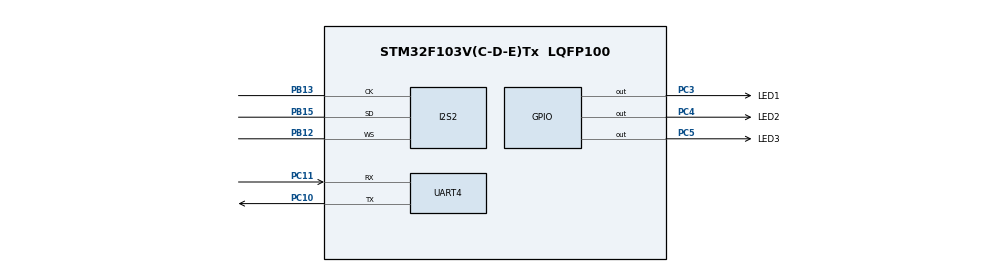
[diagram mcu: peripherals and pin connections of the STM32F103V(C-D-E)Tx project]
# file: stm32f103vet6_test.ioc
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I2S2.ErrorAudioFreq=0.8 %
I2S2.Instance=SPI$Index
I2S2.RealAudioFreq=8.064 KHz
I2S2.VirtualMode=I2S_MODE_SLAVE
Mcu.Family=STM32F1
Mcu.Name=STM32F103V(C-D-E)Tx
Mcu.Package=LQFP100
NVIC.PriorityGroup=NVIC_PRIORITYGROUP_4
PA13.Mode=JTAG_5_pins
PA13.Signal=SYS_JTMS-SWDIO
PA14.Mode=JTAG_5_pins
PA14.Signal=SYS_JTCK-SWCLK
PA15.Mode=JTAG_5_pins
PA15.Signal=SYS_JTDI
PB12.Mode=Half_Duplex_Slave_RX
PB12.Signal=I2S2_WS
PB13.Mode=Half_Duplex_Slave_RX
PB13.Signal=I2S2_CK
PB15.Mode=Half_Duplex_Slave_RX
PB15.Signal=I2S2_SD
PB3.Mode=JTAG_5_pins
PB3.Signal=SYS_JTDO-TRACESWO
PB4.Mode=JTAG_5_pins
PB4.Signal=SYS_NJTRST
PC10.Mode=Asynchronous
PC10.Signal=UART4_TX
PC11.Mode=Asynchronous
PC11.Signal=UART4_RX
PC3.GPIO_Label=LED1
PC3.PinState=GPIO_PIN_SET
PC3.Signal=GPIO_Output
PC4.GPIO_Label=LED2
PC4.PinState=GPIO_PIN_SET
PC4.Signal=GPIO_Output
PC5.GPIO_Label=LED3
PC5.PinState=GPIO_PIN_SET
PC5.Signal=GPIO_Output
ProjectManager.HeapSize=0x200
ProjectManager.StackSize=0x400
ProjectManager.TargetToolchain=SW4STM32
RCC.APB1Freq_Value=8000000
RCC.APB2Freq_Value=8000000
UART4.VirtualMode=Asynchronous
board=custom

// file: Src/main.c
/* USER CODE BEGIN Header */
/**
  ******************************************************************************
  * @file           : main.c
  * @brief          : Main program body
  ******************************************************************************
  * @attention
  *
  * <h2><center>&copy; Copyright (c) 2021 STMicroelectronics.
  * All rights reserved.</center></h2>
  *
  * This software component is licensed by ST under BSD 3-Clause license,
  * the "License"; You may not use this file except in compliance with the
  * License. You may obtain a copy of the License at:
  *                        opensource.org/licenses/BSD-3-Clause
  *
  ******************************************************************************
  */
/* USER CODE END Header */
#include "main.h"

I2S_HandleTypeDef hi2s2;

UART_HandleTypeDef huart4;

void SystemClock_Config(void);
static void MX_GPIO_Init(void);
static void MX_I2S2_Init(void);
static void MX_UART4_Init(void);

int main(void)
{

  /* MCU Configuration--------------------------------------------------------*/

  /* Reset of all peripherals, Initializes the Flash interface and the Systick. */
  HAL_Init();

  /* Configure the system clock */
  SystemClock_Config();

  /* Initialize all configured peripherals */
  MX_GPIO_Init();
  MX_I2S2_Init();
  MX_UART4_Init();

  /* Infinite loop */
  /* USER CODE BEGIN WHILE */
  while (1)
  {
      HAL_GPIO_WritePin(LED1_GPIO_Port,LED1_Pin,GPIO_PIN_SET);
      HAL_GPIO_WritePin(LED1_GPIO_Port,LED1_Pin,GPIO_PIN_RESET);
    /* USER CODE END WHILE */

  }
}

void SystemClock_Config(void)
{
  RCC_OscInitTypeDef RCC_OscInitStruct = {0};
  RCC_ClkInitTypeDef RCC_ClkInitStruct = {0};
  RCC_PeriphCLKInitTypeDef PeriphClkInit = {0};

  /** Initializes the RCC Oscillators according to the specified parameters
  * in the RCC_OscInitTypeDef structure.
  */
  RCC_OscInitStruct.OscillatorType = RCC_OSCILLATORTYPE_HSI;
  RCC_OscInitStruct.HSIState = RCC_HSI_ON;
  RCC_OscInitStruct.HSICalibrationValue = RCC_HSICALIBRATION_DEFAULT;
  RCC_OscInitStruct.PLL.PLLState = RCC_PLL_NONE;
  if (HAL_RCC_OscConfig(&RCC_OscInitStruct) != HAL_OK)
  {
    Error_Handler();
  }
  /** Initializes the CPU, AHB and APB buses clocks
  */
  RCC_ClkInitStruct.ClockType = RCC_CLOCKTYPE_HCLK|RCC_CLOCKTYPE_SYSCLK
                              |RCC_CLOCKTYPE_PCLK1|RCC_CLOCKTYPE_PCLK2;
  RCC_ClkInitStruct.SYSCLKSource = RCC_SYSCLKSOURCE_HSI;
  RCC_ClkInitStruct.AHBCLKDivider = RCC_SYSCLK_DIV1;
  RCC_ClkInitStruct.APB1CLKDivider = RCC_HCLK_DIV1;
  RCC_ClkInitStruct.APB2CLKDivider = RCC_HCLK_DIV1;

  if (HAL_RCC_ClockConfig(&RCC_ClkInitStruct, FLASH_LATENCY_0) != HAL_OK)
  {
    Error_Handler();
  }
  PeriphClkInit.PeriphClockSelection = RCC_PERIPHCLK_I2S2;
  PeriphClkInit.I2s2ClockSelection = RCC_I2S2CLKSOURCE_SYSCLK;
  if (HAL_RCCEx_PeriphCLKConfig(&PeriphClkInit) != HAL_OK)
  {
    Error_Handler();
  }
}

static void MX_I2S2_Init(void)
{

  hi2s2.Instance = SPI2;
  hi2s2.Init.Mode = I2S_MODE_SLAVE_RX;
  hi2s2.Init.Standard = I2S_STANDARD_PHILIPS;
  hi2s2.Init.DataFormat = I2S_DATAFORMAT_16B;
  hi2s2.Init.MCLKOutput = I2S_MCLKOUTPUT_DISABLE;
  hi2s2.Init.AudioFreq = I2S_AUDIOFREQ_8K;
  hi2s2.Init.CPOL = I2S_CPOL_LOW;
  if (HAL_I2S_Init(&hi2s2) != HAL_OK)
  {
    Error_Handler();
  }

}

static void MX_UART4_Init(void)
{

  huart4.Instance = UART4;
  huart4.Init.BaudRate = 115200;
  huart4.Init.WordLength = UART_WORDLENGTH_8B;
  huart4.Init.StopBits = UART_STOPBITS_1;
  huart4.Init.Parity = UART_PARITY_NONE;
  huart4.Init.Mode = UART_MODE_TX_RX;
  huart4.Init.HwFlowCtl = UART_HWCONTROL_NONE;
  huart4.Init.OverSampling = UART_OVERSAMPLING_16;
  if (HAL_UART_Init(&huart4) != HAL_OK)
  {
    Error_Handler();
  }

}

static void MX_GPIO_Init(void)
{
  GPIO_InitTypeDef GPIO_InitStruct = {0};

  /* GPIO Ports Clock Enable */
  __HAL_RCC_GPIOC_CLK_ENABLE();
  __HAL_RCC_GPIOB_CLK_ENABLE();
  __HAL_RCC_GPIOA_CLK_ENABLE();

  /*Configure GPIO pin Output Level */
  HAL_GPIO_WritePin(GPIOC, LED1_Pin|LED2_Pin|LED3_Pin, GPIO_PIN_SET);

  /*Configure GPIO pins : LED1_Pin LED2_Pin LED3_Pin */
  GPIO_InitStruct.Pin = LED1_Pin|LED2_Pin|LED3_Pin;
  GPIO_InitStruct.Mode = GPIO_MODE_OUTPUT_PP;
  GPIO_InitStruct.Pull = GPIO_NOPULL;
  GPIO_InitStruct.Speed = GPIO_SPEED_FREQ_LOW;
  HAL_GPIO_Init(GPIOC, &GPIO_InitStruct);

}

void Error_Handler(void)
{
  __disable_irq();
  while (1)
  {
  }
}

/************************ (C) COPYRIGHT STMicroelectronics *****END OF FILE****/
